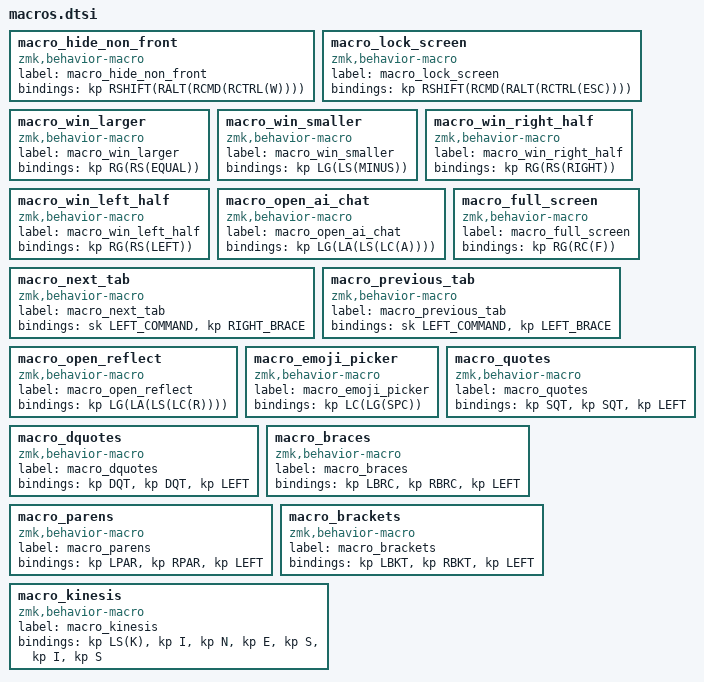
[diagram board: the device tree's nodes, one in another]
macro_hide_non_front: macro_hide_non_front{
compatible = "zmk,behavior-macro";
label = "macro_hide_non_front";
#binding-cells = <0>;
bindings = <&kp RSHIFT(RALT(RCMD(RCTRL(W))))>;
};
macro_lock_screen: macro_lock_screen{
compatible = "zmk,behavior-macro";
label = "macro_lock_screen";
#binding-cells = <0>;
bindings = <&kp RSHIFT(RCMD(RALT(RCTRL(ESC))))>;
};
macro_win_larger: macro_win_larger{
compatible = "zmk,behavior-macro";
label = "macro_win_larger";
#binding-cells = <0>;
bindings = <&kp RG(RS(EQUAL))>;
};
macro_win_smaller: macro_win_smaller{
compatible = "zmk,behavior-macro";
label = "macro_win_smaller";
#binding-cells = <0>;
bindings = <&kp LG(LS(MINUS))>;
};
macro_win_right_half: macro_win_right_half{
compatible = "zmk,behavior-macro";
label = "macro_win_right_half";
#binding-cells = <0>;
bindings = <&kp RG(RS(RIGHT))>;
};
macro_win_left_half: macro_win_left_half{
compatible = "zmk,behavior-macro";
label = "macro_win_left_half";
#binding-cells = <0>;
bindings = <&kp RG(RS(LEFT))>;
};
macro_open_ai_chat: macro_open_ai_chat{
compatible = "zmk,behavior-macro";
label = "macro_open_ai_chat";
#binding-cells = <0>;
bindings = <&kp LG(LA(LS(LC(A))))>;
};
macro_full_screen: macro_full_screen{
compatible = "zmk,behavior-macro";
label = "macro_full_screen";
#binding-cells = <0>;
bindings = <&kp RG(RC(F))>;
};
macro_next_tab: macro_next_tab{
compatible = "zmk,behavior-macro";
label = "macro_next_tab";
#binding-cells = <0>;
bindings = <&sk LEFT_COMMAND>, <&kp RIGHT_BRACE>;
};
macro_previous_tab: macro_previous_tab{
compatible = "zmk,behavior-macro";
label = "macro_previous_tab";
#binding-cells = <0>;
bindings = <&sk LEFT_COMMAND>, <&kp LEFT_BRACE>;
};
macro_open_reflect: macro_open_reflect{
compatible = "zmk,behavior-macro";
label = "macro_open_reflect";
#binding-cells = <0>;
bindings = <&kp LG(LA(LS(LC(R))))>;
};
macro_emoji_picker: macro_emoji_picker{
compatible = "zmk,behavior-macro";
label = "macro_emoji_picker";
#binding-cells = <0>;
bindings = <&kp LC(LG(SPC))>;
};
macro_quotes: macro_quotes{
compatible = "zmk,behavior-macro";
label = "macro_quotes";
#binding-cells = <0>;
bindings = <&kp SQT>, <&kp SQT>, <&kp LEFT>;
};
macro_dquotes: macro_dquotes{
compatible = "zmk,behavior-macro";
label = "macro_dquotes";
#binding-cells = <0>;
bindings = <&kp DQT>, <&kp DQT>, <&kp LEFT>;
};
macro_braces: macro_braces{
compatible = "zmk,behavior-macro";
label = "macro_braces";
#binding-cells = <0>;
bindings = <&kp LBRC>, <&kp RBRC>, <&kp LEFT>;
};
macro_parens: macro_parens{
compatible = "zmk,behavior-macro";
label = "macro_parens";
#binding-cells = <0>;
bindings = <&kp LPAR>, <&kp RPAR>, <&kp LEFT>;
};
macro_brackets: macro_brackets{
compatible = "zmk,behavior-macro";
label = "macro_brackets";
#binding-cells = <0>;
bindings = <&kp LBKT>, <&kp RBKT>, <&kp LEFT>;
};
macro_kinesis: macro_kinesis{
compatible = "zmk,behavior-macro";
label = "macro_kinesis";
#binding-cells = <0>;
bindings = <&kp LS(K)>, <&kp I>, <&kp N>, <&kp E>, <&kp S>, <&kp I>, <&kp S>;
};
